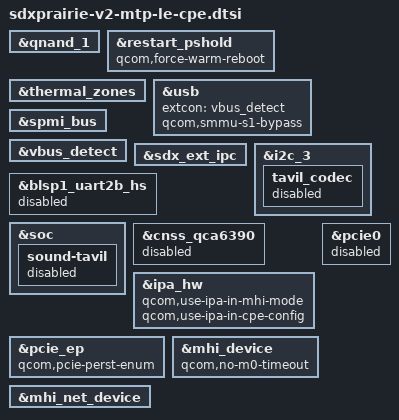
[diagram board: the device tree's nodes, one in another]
/* Copyright (c) 2019-2020, The Linux Foundation. All rights reserved.
 *
 * This program is free software; you can redistribute it and/or modify
 * it under the terms of the GNU General Public License version 2 and
 * only version 2 as published by the Free Software Foundation.
 *
 * This program is distributed in the hope that it will be useful,
 * but WITHOUT ANY WARRANTY; without even the implied warranty of
 * MERCHANTABILITY or FITNESS FOR A PARTICULAR PURPOSE.  See the
 * GNU General Public License for more details.
 */

#include "sdxprairie-v2.dtsi"
#include "sdxprairie-mtp.dtsi"

/delete-node/ &pm8150b_fg;
/delete-node/ &pm8150b_bcl;
/delete-node/ &pm8150b_pdphy;
/delete-node/ &pm8150b_charger;
/delete-node/ &pm8150b_adc_tm;
/delete-node/ &pm8150b_vadc;

&qnand_1 {
	status = "ok";
};

&restart_pshold {
	qcom,force-warm-reboot;
};

/* delete pm8150b nodes */
&thermal_zones {
	/delete-node/ pm8150b-wp-therm;
	/delete-node/ pm8150b_tz;
	/delete-node/ pm8150b-ibat-lvl0;
	/delete-node/ pm8150b-ibat-lvl1;
	/delete-node/ pm8150b-vbat-lvl0;
	/delete-node/ pm8150b-vbat-lvl1;
	/delete-node/ pm8150b-vbat-lvl2;
	/delete-node/ pm8150b-bcl-lvl0;
	/delete-node/ pm8150b-bcl-lvl1;
	/delete-node/ pm8150b-bcl-lvl2;
	/delete-node/ soc;
};

&usb {
	extcon = <&vbus_detect>;
	qcom,smmu-s1-bypass;
};

&spmi_bus {
	/delete-node/ qcom,pm8150b@2;
	/delete-node/ qcom,pm8150b@3;
};

&vbus_detect {
	status = "ok";
};

&sdx_ext_ipc {
	status = "ok";
};

&i2c_3 {
	tavil_codec {
		status = "disabled";
	};
};

&blsp1_uart2b_hs {
	status = "disabled";
};

&soc {
	sound-tavil {
		status = "disabled";
	};
};

&cnss_qca6390 {
	status = "disabled";
};

&ipa_hw {
	qcom,use-ipa-in-mhi-mode;
	qcom,use-ipa-in-cpe-config;
};

&pcie0 {
	status = "disabled";
};

&pcie_ep {
	status = "ok";
	qcom,pcie-perst-enum;
};

&mhi_device {
	status = "ok";
	qcom,no-m0-timeout;
};

&mhi_net_device {
	status = "ok";
};
